# TMS320F280049 register map
Vendor: Texas Instruments; Series: C2000 F28004x; File version: 0.2.0-generated
Registers are 16-bit, read-write, reset 0x0 unless marked. A register's access mark holds for its fields unless they carry their own. Offsets are from the block's base; [hi:lo] are bit positions; {n}, {i} and the like mark numbered series.

## NMIINTRUPTREGS — NMI INTRUPT Registers
Base 0x0000E0C0
0x00 NMICFG — NMI Configuration Register
  [0] NMIE — Global NMI Enable
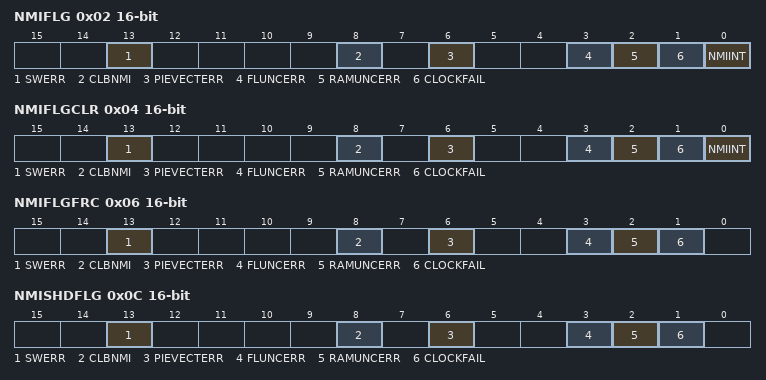
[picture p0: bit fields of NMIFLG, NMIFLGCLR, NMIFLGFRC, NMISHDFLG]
0x02 NMIFLG — NMI Flag Register (SYSRsn Clear)
  [13] SWERR — SW Error Force NMI Flag
  [8] CLBNMI — Configurable Logic Block NMI Flag
  [6] PIEVECTERR — PIE Vector Fetch Error Flag
  [3] FLUNCERR — Flash Uncorrectable Error NMI Flag
  [2] RAMUNCERR — RAM Uncorrectable Error NMI Flag
  [1] CLOCKFAIL — Clock Fail Interrupt Flag
  [0] NMIINT — NMI Interrupt Flag
0x04 NMIFLGCLR — NMI Flag Clear Register
  [13] SWERR — SWERR Flag Clear
  [8] CLBNMI — CLBNMI Flag Clear
  [6] PIEVECTERR — PIEVECTERR Flag Clear
  [3] FLUNCERR — FLUNCERR Flag Clear
  [2] RAMUNCERR — RAMUNCERR Flag Clear
  [1] CLOCKFAIL — CLOCKFAIL Flag Clear
  [0] NMIINT — NMIINT Flag Clear
0x06 NMIFLGFRC — NMI Flag Force Register
  [13] SWERR — SWERR Flag Force
  [8] CLBNMI — CLBNMI Flag Force
  [6] PIEVECTERR — PIEVECTERR Flag Force
  [3] FLUNCERR — FLUNCERR Flag Force
  [2] RAMUNCERR — RAMUNCERR Flag Force
  [1] CLOCKFAIL — CLOCKFAIL Flag Force
0x08 NMIWDCNT — NMI Watchdog Counter Register
  [15] NMIWDCNT — NMI Watchdog Counter
0x0A NMIWDPRD — NMI Watchdog Period Register
  [15] NMIWDPRD — NMI Watchdog Period
0x0C NMISHDFLG — NMI Shadow Flag Register
  [13] SWERR — SW Error Force NMI Flag
  [8] CLBNMI — Shadow CLBNMI flag
  [6] PIEVECTERR — Shadow PIEVECTERR Flag
  [3] FLUNCERR — Shadow FLUNCERR Flag
  [2] RAMUNCERR — Shadow RAMUNCERR Flag
  [1] CLOCKFAIL — Shadow CLOCKFAIL Flag

## XINTREGS — XINT Registers
Base 0x0000E0E0
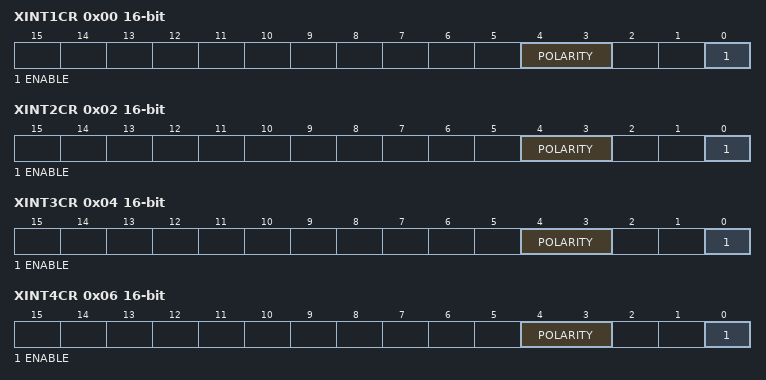
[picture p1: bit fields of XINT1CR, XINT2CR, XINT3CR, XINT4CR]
0x00 XINT1CR — XINT1 configuration register
  [4:3] POLARITY — XINT1 Polarity
  [0] ENABLE — XINT1 Enable
0x02 XINT2CR — XINT2 configuration register
  [4:3] POLARITY — XINT2 Polarity
  [0] ENABLE — XINT2 Enable
0x04 XINT3CR — XINT3 configuration register
  [4:3] POLARITY — XINT3 Polarity
  [0] ENABLE — XINT3 Enable
0x06 XINT4CR — XINT4 configuration register
  [4:3] POLARITY — XINT4 Polarity
  [0] ENABLE — XINT4 Enable
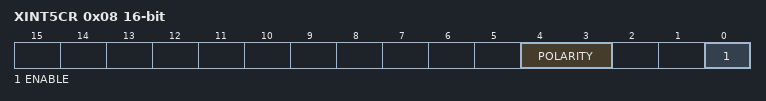
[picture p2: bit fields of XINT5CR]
0x08 XINT5CR — XINT5 configuration register
  [4:3] POLARITY — XINT5 Polarity
  [0] ENABLE — XINT5 Enable
{0xE+2i} XINT{i}CTR (i=1..3) — XINT{i} counter register
  [15] INTCTR — XINT{i} Counter

## SCIAREGS — SCI Registers
Base 0x0000E400
Same registers: SCIBREGS 0x0000E420
0x00 SCICCR — Communications control register
  [7] STOPBITS — Number of Stop Bits
  [6] PARITY — Even or Odd Parity
  [5] PARITYENA — Parity enable
  [4] LOOPBKENA — Loop Back enable
  [3] ADDRIDLE_MODE — ADDR/IDLE Mode control
  [4:2] SCICHAR — Character length control
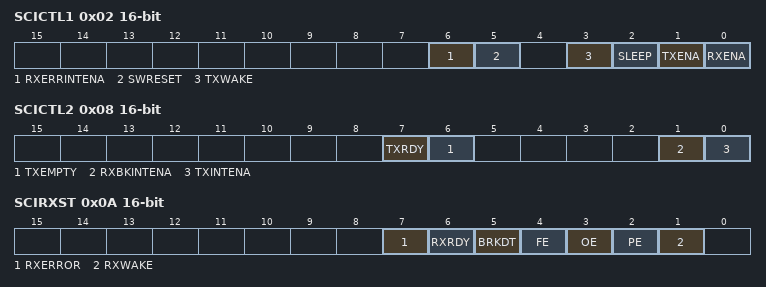
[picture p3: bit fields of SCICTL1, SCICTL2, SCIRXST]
0x02 SCICTL1 — Control register 1
  [6] RXERRINTENA — Receive error interrupt enable
  [5] SWRESET — Software reset
  [3] TXWAKE — Transmitter wakeup method
  [2] SLEEP — SCI sleep
  [1] TXENA — SCI transmitter enable
  [0] RXENA — SCI receiver enable
0x04 SCIHBAUD — Baud rate (high) register
  [14:7] BAUD — SCI 16-bit baud selection Registers SCIHBAUD
0x06 SCILBAUD — Baud rate (low) register
  [14:7] BAUD — SCI 16-bit baud selection Registers SCILBAUD
0x08 SCICTL2 — Control register 2
  [7] TXRDY — Transmitter ready flag
  [6] TXEMPTY — Transmitter empty flag
  [1] RXBKINTENA — Receiver-buffer break enable
  [0] TXINTENA — Transmit __interrupt enable
0x0A SCIRXST — Receive status register
  [7] RXERROR — Receiver error flag
  [6] RXRDY — Receiver ready flag
  [5] BRKDT — Break-detect flag
  [4] FE — Framing error flag
  [3] OE — Overrun error flag
  [2] PE — Parity error flag
  [1] RXWAKE — Receiver wakeup detect flag
0x0C SCIRXEMU — Receive emulation buffer register
  [14:7] ERXDT — Receive emulation buffer data
0x0E SCIRXBUF — Receive data buffer
  [15] SCIFFFE — Receiver error flag
  [14] SCIFFPE — Receiver error flag
  [14:7] SAR — Receive Character bits
0x12 SCITXBUF — Transmit data buffer
  [14:7] TXDT
0x14 SCIFFTX — FIFO transmit register
  [15] SCIRST — SCI reset rx/tx channels
  [14] SCIFFENA — Enhancement enable
  [13] TXFIFORESET — FIFO reset
  [15:12] TXFFST — FIFO status
  [7] TXFFINT — INT flag
  [6] TXFFINTCLR — Clear INT flag
  [5] TXFFIENA — Interrupt enable
  [8:4] TXFFIL — Interrupt level
0x16 SCIFFRX — FIFO receive register
  [15] RXFFOVF — FIFO overflow
  [14] RXFFOVRCLR — Clear overflow
  [13] RXFIFORESET — FIFO reset
  [15:12] RXFFST — FIFO status
  [7] RXFFINT — INT flag
  [6] RXFFINTCLR — Clear INT flag
  [5] RXFFIENA — Interrupt enable
  [8:4] RXFFIL — Interrupt level
0x18 SCIFFCT — FIFO control register
  [15] ABD — Auto baud detect
  [14] ABDCLR — Auto baud clear
  [13] CDC — Auto baud mode enable
  [14:7] FFTXDLY — FIFO transmit delay
0x1E SCIPRI — SCI priority control
  [5:4] FREESOFT — Emulation modes
